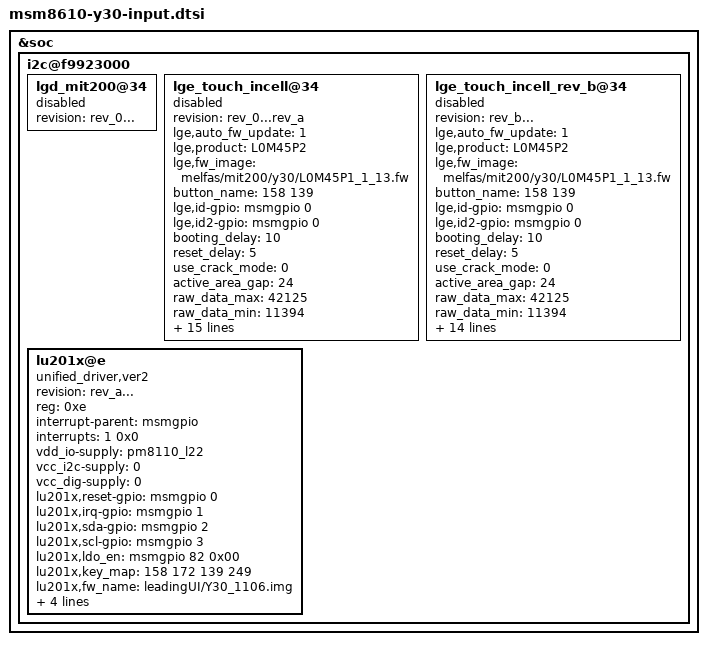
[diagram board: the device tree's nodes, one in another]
/* Copyright (c) 2012, Code Aurora Forum. All rights reserved.
 *
 * This program is free software; you can redistribute it and/or modify
 * it under the terms of the GNU General Public License version 2 and
 * only version 2 as published by the Free Software Foundation.
 *
 * This program is distributed in the hope that it will be useful,
 * but WITHOUT ANY WARRANTY; without even the implied warranty of
 * MERCHANTABILITY or FITNESS FOR A PARTICULAR PURPOSE.  See the
 * GNU General Public License for more details.
 */
&soc {
	i2c@f9923000{
		lgd_mit200@34 {
			revision = "rev_0...";
			status = "disable";
		};
		lge_touch_incell@34 {
			revision = "rev_0...rev_a";
			status = "disable";
			lge,auto_fw_update = <1>;
			lge,product = "L0M45P2";
			lge,fw_image = "melfas/mit200/y30/L0M45P1_1_13.fw";
			button_name = <158 139>;
			lge,id-gpio = <&msmgpio 0 0x00>;
			lge,id2-gpio = <&msmgpio 0 0x00>;
			booting_delay = <10>;
                        reset_delay = <5>;
                        use_crack_mode = <0>;
			active_area_gap = <24>;
			
			/* Limitation Value. */
			raw_data_max = <42125>;
			raw_data_min = <11394>;
			raw_data_margin = <1000>;
			raw_data_otp_min = <15000>;
			raw_data_otp_max = <39000>;
			open_short_min = <10>;
			slope_max = <110>;
			slope_min = <90>;  			
			
			/* panel status check */
                        openshort_enable = <1>;

			/* platform_data->pwr*/
			/* type 0: none(default) */
			/*      1: gpio */
			/*      2: regulator */
			/* name if type == 1, gpio active condition "low" or "high" */
			/*      if type == 2, sypply name for regulator */
			/* value if type == 1, gpio pin no. */
			/*       if type == 2, regulator voltage */
			vdd_type0 = <1>;
			vdd_name0 = "high";
			vdd_value0 = <82>;
			vdd-supply = <0>;
			vdd_type1 = <2>;
			vdd_name1 = "vdd_io";
			vdd_value1 = <1800000>;
			vdd_io-supply = <&pm8110_l8>;
			
			//vdd_type2 = <2>;
			//vdd_name2 = "vio_int";
			//vdd_value2 = <1800000>;
			//vio_int-supply = <&pm8110_l8>;
		};
                lge_touch_incell_rev_b@34 {
			revision = "rev_b...";
			status = "disable";
			lge,auto_fw_update = <1>;
			lge,product = "L0M45P2";
			lge,fw_image = "melfas/mit200/y30/L0M45P1_1_13.fw";
			button_name = <158 139>;
			lge,id-gpio = <&msmgpio 0 0x00>;
			lge,id2-gpio = <&msmgpio 0 0x00>;
			booting_delay = <10>;
                        reset_delay = <5>;
                        use_crack_mode = <0>;
			active_area_gap = <24>;

			/* Limitation Value. */
			raw_data_max = <42125>;
			raw_data_min = <11394>;
			raw_data_margin = <1000>;
			raw_data_otp_min = <15000>;
			raw_data_otp_max = <39000>;
			open_short_min = <10>;
			slope_max = <110>;
			slope_min = <90>;                        
			
			/* panel status check */
                        openshort_enable = <1>;

			/* platform_data->pwr*/
			/* type 0: none(default) */
			/*      1: gpio */
			/*      2: regulator */
			/* name if type == 1, gpio active condition "low" or "high" */
			/*      if type == 2, sypply name for regulator */
			/* value if type == 1, gpio pin no. */
			/*       if type == 2, regulator voltage */
			vdd_type0 = <1>;
			vdd_name0 = "high";
			vdd_value0 = <76>;
			vdd-supply = <0>;
			vdd_type1 = <1>;
			vdd_name1 = "high";
			vdd_value1 = <82>;
			vdd-supply = <0>;
			//vdd_type1 = <2>;
			//vdd_name1 = "vdd_io";
			//vdd_value1 = <1800000>;
			//vdd_io-supply = <&pm8110_l8>;
			//vdd_type2 = <2>;
			//vdd_name2 = "vio_int";
			//vdd_value2 = <1800000>;
			//vio_int-supply = <&pm8110_l8>;
		}; 
		/*unified Driver 2.0*/
		lu201x@e {
			compatible = "unified_driver,ver2"; 
			revision = "rev_a...";
			reg = <0xe>;
			status = "ok";

			interrupt-parent = <&msmgpio>;
			interrupts = <1 0x0>;
			vdd_io-supply = <&pm8110_l22>;
			vcc_i2c-supply = <0>;
			vcc_dig-supply = <0>;

			lu201x,reset-gpio = <&msmgpio 0 0x00>;
			lu201x,irq-gpio = <&msmgpio 1 0x00>;
			lu201x,sda-gpio = <&msmgpio 2 0x00>;
			lu201x,scl-gpio = <&msmgpio 3 0x00>;
			lu201x,ldo_en = <&msmgpio 82 0x00>;

			lu201x,key_map = <158 172 139 249>;
			lu201x,fw_name = "leadingUI/Y30_1106.img";
			lu201x,global_access_pixel = <10>;
			lu201x,num_touch = <2>;
			lu201x,max_x = <480>;
			lu201x,max_y = <800>;
		};
	};
};
